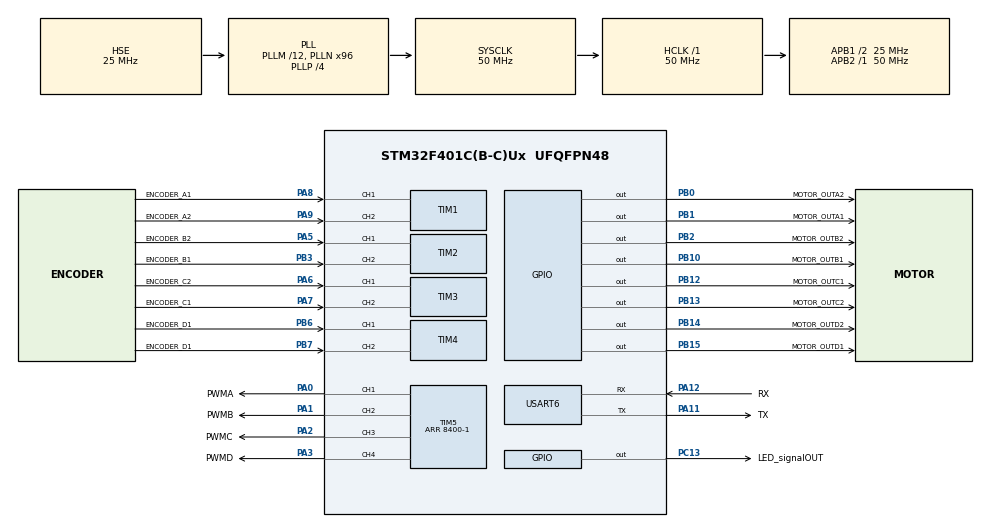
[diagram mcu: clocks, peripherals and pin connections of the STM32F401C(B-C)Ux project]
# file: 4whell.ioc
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Dma.Request0=USART6_TX
Dma.Request1=USART6_RX
Dma.USART6_RX.1.Direction=DMA_PERIPH_TO_MEMORY
Dma.USART6_RX.1.FIFOMode=DMA_FIFOMODE_DISABLE
Dma.USART6_RX.1.Instance=DMA2_Stream1
Dma.USART6_RX.1.MemDataAlignment=DMA_MDATAALIGN_BYTE
Dma.USART6_RX.1.MemInc=DMA_MINC_ENABLE
Dma.USART6_RX.1.Mode=DMA_NORMAL
Dma.USART6_RX.1.PeriphDataAlignment=DMA_PDATAALIGN_BYTE
Dma.USART6_RX.1.PeriphInc=DMA_PINC_DISABLE
Dma.USART6_RX.1.Priority=DMA_PRIORITY_LOW
Dma.USART6_TX.0.Direction=DMA_MEMORY_TO_PERIPH
Dma.USART6_TX.0.FIFOMode=DMA_FIFOMODE_DISABLE
Dma.USART6_TX.0.Instance=DMA2_Stream6
Dma.USART6_TX.0.MemDataAlignment=DMA_MDATAALIGN_BYTE
Dma.USART6_TX.0.MemInc=DMA_MINC_ENABLE
Dma.USART6_TX.0.Mode=DMA_NORMAL
Dma.USART6_TX.0.PeriphDataAlignment=DMA_PDATAALIGN_BYTE
Dma.USART6_TX.0.PeriphInc=DMA_PINC_DISABLE
Dma.USART6_TX.0.Priority=DMA_PRIORITY_LOW
FREERTOS.Tasks01=defaultTask,24,128,StartDefaultTask,Default,NULL,Dynamic,NULL,NULL
Mcu.Family=STM32F4
Mcu.Name=STM32F401C(B-C)Ux
Mcu.Package=UFQFPN48
NVIC.DMA2_Stream1_IRQn=true\:5\:0\:false\:false\:true\:true\:false\:true\:true
NVIC.DMA2_Stream6_IRQn=true\:5\:0\:false\:false\:true\:true\:false\:true\:true
NVIC.PriorityGroup=NVIC_PRIORITYGROUP_4
NVIC.TIM1_BRK_TIM9_IRQn=true\:5\:0\:false\:false\:true\:true\:true\:true\:true
NVIC.TIM1_TRG_COM_TIM11_IRQn=true\:5\:0\:false\:false\:true\:false\:false\:true\:true
NVIC.TIM1_UP_TIM10_IRQn=true\:5\:0\:false\:false\:true\:false\:false\:true\:true
NVIC.USART6_IRQn=true\:5\:0\:false\:false\:true\:true\:false\:true\:true
PA0-WKUP.GPIO_Label=PWMA
PA0-WKUP.Signal=S_TIM5_CH1
PA1.GPIO_Label=PWMB
PA1.Signal=S_TIM5_CH2
PA11.GPIO_Label=TX
PA11.Mode=Asynchronous
PA11.Signal=USART6_TX
PA12.GPIO_Label=RX
PA12.Mode=Asynchronous
PA12.Signal=USART6_RX
PA13.Mode=Serial_Wire
PA13.Signal=SYS_JTMS-SWDIO
PA14.Mode=Serial_Wire
PA14.Signal=SYS_JTCK-SWCLK
PA2.GPIO_Label=PWMC
PA2.Signal=S_TIM5_CH3
PA3.GPIO_Label=PWMD
PA3.Signal=S_TIM5_CH4
PA5.GPIO_Label=ENCODER_B2
PA5.Signal=S_TIM2_CH1_ETR
PA6.GPIO_Label=ENCODER_C2
PA6.Signal=S_TIM3_CH1
PA7.GPIO_Label=ENCODER_C1
PA7.Signal=S_TIM3_CH2
PA8.GPIO_Label=ENCODER_A1
PA8.Signal=S_TIM1_CH1
PA9.GPIO_Label=ENCODER_A2
PA9.Signal=S_TIM1_CH2
PB0.GPIO_Label=MOTOR_OUTA2
PB0.GPIO_Speed=GPIO_SPEED_FREQ_HIGH
PB0.Signal=GPIO_Output
PB1.GPIO_Label=MOTOR_OUTA1
PB1.GPIO_Speed=GPIO_SPEED_FREQ_HIGH
PB1.Signal=GPIO_Output
PB10.GPIO_Label=MOTOR_OUTB1
PB10.GPIO_Speed=GPIO_SPEED_FREQ_HIGH
PB10.Signal=GPIO_Output
PB12.GPIO_Label=MOTOR_OUTC1
PB12.GPIO_Speed=GPIO_SPEED_FREQ_HIGH
PB12.Signal=GPIO_Output
PB13.GPIO_Label=MOTOR_OUTC2
PB13.GPIO_Speed=GPIO_SPEED_FREQ_HIGH
PB13.Signal=GPIO_Output
PB14.GPIO_Label=MOTOR_OUTD2
PB14.GPIO_Speed=GPIO_SPEED_FREQ_HIGH
PB14.Signal=GPIO_Output
PB15.GPIO_Label=MOTOR_OUTD1
PB15.GPIO_Speed=GPIO_SPEED_FREQ_HIGH
PB15.Signal=GPIO_Output
PB2.GPIO_Label=MOTOR_OUTB2
PB2.GPIO_Speed=GPIO_SPEED_FREQ_HIGH
PB2.Signal=GPIO_Output
PB3.GPIO_Label=ENCODER_B1
PB3.Signal=S_TIM2_CH2
PB6.GPIO_Label=ENCODER_D1
PB6.Signal=S_TIM4_CH1
PB7.GPIO_Label=ENCODER_D1
PB7.Signal=S_TIM4_CH2
PC13-ANTI_TAMP.GPIO_Label=LED_signalOUT
PC13-ANTI_TAMP.PinState=GPIO_PIN_SET
PC13-ANTI_TAMP.Signal=GPIO_Output
PH0\ -\ OSC_IN.Mode=HSE-External-Oscillator
PH0\ -\ OSC_IN.Signal=RCC_OSC_IN
PH1\ -\ OSC_OUT.Mode=HSE-External-Oscillator
PH1\ -\ OSC_OUT.Signal=RCC_OSC_OUT
ProjectManager.HeapSize=0x200
ProjectManager.StackSize=0x400
ProjectManager.TargetToolchain=Makefile
RCC.48MHZClocksFreq_Value=50000000
RCC.AHBFreq_Value=50000000
RCC.APB1CLKDivider=RCC_HCLK_DIV2
RCC.APB1Freq_Value=25000000
RCC.APB1TimFreq_Value=50000000
RCC.APB2Freq_Value=50000000
RCC.APB2TimFreq_Value=50000000
RCC.CortexFreq_Value=50000000
RCC.HCLKFreq_Value=50000000
RCC.HSE_VALUE=25000000
RCC.HSI_VALUE=16000000
RCC.LSE_VALUE=32768
RCC.PLLM=12
RCC.PLLN=96
RCC.PLLP=RCC_PLLP_DIV4
RCC.PLLSourceVirtual=RCC_PLLSOURCE_HSE
RCC.SYSCLKFreq_VALUE=50000000
RCC.SYSCLKSource=RCC_SYSCLKSOURCE_PLLCLK
RCC.VCOOutputFreq_Value=200000000
SH.S_TIM1_CH1.0=TIM1_CH1,Encoder_Interface
SH.S_TIM1_CH2.0=TIM1_CH2,Encoder_Interface
SH.S_TIM2_CH1_ETR.0=TIM2_CH1,Encoder_Interface
SH.S_TIM2_CH2.0=TIM2_CH2,Encoder_Interface
SH.S_TIM3_CH1.0=TIM3_CH1,Encoder_Interface
SH.S_TIM3_CH2.0=TIM3_CH2,Encoder_Interface
SH.S_TIM4_CH1.0=TIM4_CH1,Encoder_Interface
SH.S_TIM4_CH2.0=TIM4_CH2,Encoder_Interface
SH.S_TIM5_CH1.0=TIM5_CH1,PWM Generation1 CH1
SH.S_TIM5_CH2.0=TIM5_CH2,PWM Generation2 CH2
SH.S_TIM5_CH3.0=TIM5_CH3,PWM Generation3 CH3
SH.S_TIM5_CH4.0=TIM5_CH4,PWM Generation4 CH4
TIM1.EncoderMode=TIM_ENCODERMODE_TI12
TIM10.Period=100-1
TIM10.Prescaler=500-1
TIM2.EncoderMode=TIM_ENCODERMODE_TI12
TIM3.EncoderMode=TIM_ENCODERMODE_TI12
TIM4.EncoderMode=TIM_ENCODERMODE_TI12
TIM5.Channel-PWM\ Generation1\ CH1=TIM_CHANNEL_1
TIM5.Channel-PWM\ Generation2\ CH2=TIM_CHANNEL_2
TIM5.Channel-PWM\ Generation3\ CH3=TIM_CHANNEL_3
TIM5.Channel-PWM\ Generation4\ CH4=TIM_CHANNEL_4
TIM5.ClockDivision=TIM_CLOCKDIVISION_DIV1
TIM5.Period=8400-1
TIM9.AutoReloadPreload=TIM_AUTORELOAD_PRELOAD_ENABLE
TIM9.Period=10000-1
TIM9.Prescaler=5000-1
USART6.VirtualMode=VM_ASYNC
VP_FREERTOS_VS_CMSIS_V2.Mode=CMSIS_V2
VP_TIM10_VS_ClockSourceINT.Mode=Enable_Timer
VP_TIM9_VS_ClockSourceINT.Mode=Internal
board=custom

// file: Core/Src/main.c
/* USER CODE BEGIN Header */
/**
  ******************************************************************************
  * @file           : main.c
  * @brief          : Main program body
  ******************************************************************************
  * @attention
  *
  * Copyright (c) 2026 STMicroelectronics.
  * All rights reserved.
  *
  * This software is licensed under terms that can be found in the LICENSE file
  * in the root directory of this software component.
  * If no LICENSE file comes with this software, it is provided AS-IS.
  *
  ******************************************************************************
  */
/* USER CODE END Header */
#include "main.h"
#include "cmsis_os.h"
#include "dma.h"
#include "tim.h"
#include "usart.h"
#include "gpio.h"

/* USER CODE BEGIN Includes */
#include "bsp_led.h"
/* USER CODE END Includes */

void SystemClock_Config(void);
void MX_FREERTOS_Init(void);

int main(void)
{

  /* MCU Configuration--------------------------------------------------------*/

  /* Reset of all peripherals, Initializes the Flash interface and the Systick. */
  HAL_Init();

  /* USER CODE BEGIN Init */
  // TB6612_Init();  目前排查下来在app_task中调用就行。
  /* USER CODE END Init */

  /* Configure the system clock */
  SystemClock_Config();

  /* Initialize all configured peripherals */
  MX_GPIO_Init();
  MX_DMA_Init();
  MX_TIM1_Init();
  MX_TIM3_Init();
  MX_TIM4_Init();
  MX_TIM5_Init();
  MX_USART6_UART_Init();
  MX_TIM9_Init();
  MX_TIM2_Init();
  MX_TIM10_Init();
  /* USER CODE BEGIN 2 */

  /* 上电示意：LED 闪两下 */
  BSP_LED_On();   HAL_Delay(100);  BSP_LED_Off();
  HAL_Delay(100);
  BSP_LED_On();   HAL_Delay(100);  BSP_LED_Off();

  /* USER CODE END 2 */

  /* Init scheduler */
  osKernelInitialize();
  MX_FREERTOS_Init();

  /* Start scheduler */
  osKernelStart();

  /* We should never get here as control is now taken by the scheduler */

  /* Infinite loop */
  while (1)
  {

  }
}

void SystemClock_Config(void)
{
  RCC_OscInitTypeDef RCC_OscInitStruct = {0};
  RCC_ClkInitTypeDef RCC_ClkInitStruct = {0};

  /** Configure the main internal regulator output voltage
  */
  __HAL_RCC_PWR_CLK_ENABLE();
  __HAL_PWR_VOLTAGESCALING_CONFIG(PWR_REGULATOR_VOLTAGE_SCALE2);

  /** Initializes the RCC Oscillators according to the specified parameters
  * in the RCC_OscInitTypeDef structure.
  */
  RCC_OscInitStruct.OscillatorType = RCC_OSCILLATORTYPE_HSE;
  RCC_OscInitStruct.HSEState = RCC_HSE_ON;
  RCC_OscInitStruct.PLL.PLLState = RCC_PLL_ON;
  RCC_OscInitStruct.PLL.PLLSource = RCC_PLLSOURCE_HSE;
  RCC_OscInitStruct.PLL.PLLM = 12;
  RCC_OscInitStruct.PLL.PLLN = 96;
  RCC_OscInitStruct.PLL.PLLP = RCC_PLLP_DIV4;
  RCC_OscInitStruct.PLL.PLLQ = 4;
  if (HAL_RCC_OscConfig(&RCC_OscInitStruct) != HAL_OK)
  {
    Error_Handler();
  }

  /** Initializes the CPU, AHB and APB buses clocks
  */
  RCC_ClkInitStruct.ClockType = RCC_CLOCKTYPE_HCLK|RCC_CLOCKTYPE_SYSCLK
                              |RCC_CLOCKTYPE_PCLK1|RCC_CLOCKTYPE_PCLK2;
  RCC_ClkInitStruct.SYSCLKSource = RCC_SYSCLKSOURCE_PLLCLK;
  RCC_ClkInitStruct.AHBCLKDivider = RCC_SYSCLK_DIV1;
  RCC_ClkInitStruct.APB1CLKDivider = RCC_HCLK_DIV2;
  RCC_ClkInitStruct.APB2CLKDivider = RCC_HCLK_DIV1;

  if (HAL_RCC_ClockConfig(&RCC_ClkInitStruct, FLASH_LATENCY_1) != HAL_OK)
  {
    Error_Handler();
  }
}

void Error_Handler(void)
{
  __disable_irq();
  while (1)
  {
  }
}

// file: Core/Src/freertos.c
/* USER CODE BEGIN Header */
/**
  ******************************************************************************
  * File Name          : freertos.c
  * Description        : Code for freertos applications
  ******************************************************************************
  * @attention
  *
  * Copyright (c) 2026 STMicroelectronics.
  * All rights reserved.
  *
  * This software is licensed under terms that can be found in the LICENSE file
  * in the root directory of this software component.
  * If no LICENSE file comes with this software, it is provided AS-IS.
  *
  ******************************************************************************
  */
/* USER CODE END Header */

#include "FreeRTOS.h"
#include "task.h"
#include "main.h"
#include "cmsis_os.h"

/* USER CODE BEGIN Includes */
#include "app_chasis.h"
#include "app_protocol.h"
#include "net_uart.h"
/* USER CODE END Includes */

/* Definitions for defaultTask */
osThreadId_t defaultTaskHandle;
const osThreadAttr_t defaultTask_attributes = {
  .name = "defaultTask",
  .stack_size = 128 * 4,
  .priority = (osPriority_t) osPriorityNormal,
};

void StartDefaultTask(void *argument);

void MX_FREERTOS_Init(void); /* (MISRA C 2004 rule 8.1) */

void MX_FREERTOS_Init(void) {

  /* Create the thread(s) */
  /* creation of defaultTask */
  defaultTaskHandle = osThreadNew(StartDefaultTask, NULL, &defaultTask_attributes);

  /* USER CODE BEGIN RTOS_THREADS */
  /* add threads, ... */
  // AppTask_Init(); 不能直接调用init函数！！会直接陷入while循环，导致后续任务无法创建和完成

  /* 创建电机测试任务 */

  /* USER CODE END RTOS_THREADS */

}

void StartDefaultTask(void *argument)
{
  /* USER CODE BEGIN StartDefaultTask */

  /* Initialize UART communication layer */
  NET_UART_Init();

  /* Initialize motor drivers, encoders, and PID controllers */
  App_ChasisInit();

  /* Start binary protocol parser + 100Hz PID control loop */
  App_Protocol_Init();

  /* Infinite loop */
  for(;;)
  {
    osDelay(100);
  }
  /* USER CODE END StartDefaultTask */
}
